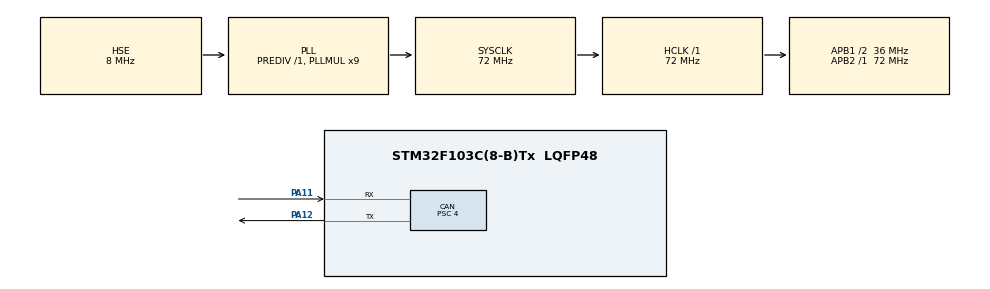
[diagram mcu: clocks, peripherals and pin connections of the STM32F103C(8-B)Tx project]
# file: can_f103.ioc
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CAN.BS1=CAN_BS1_11TQ
CAN.BS2=CAN_BS2_6TQ
CAN.CalculateBaudRate=500000
CAN.CalculateTimeBit=2000
CAN.CalculateTimeQuantum=111.11111111111111
CAN.Mode=CAN_MODE_LOOPBACK
CAN.Prescaler=4
CAN.SJW=CAN_SJW_1TQ
Mcu.Family=STM32F1
Mcu.Name=STM32F103C(8-B)Tx
Mcu.Package=LQFP48
NVIC.CAN1_RX1_IRQn=true\:0\:0\:false\:false\:true\:true\:true\:true
NVIC.CAN1_SCE_IRQn=true\:0\:0\:false\:false\:true\:true\:true\:true
NVIC.PriorityGroup=NVIC_PRIORITYGROUP_4
NVIC.TIM1_UP_IRQn=true\:0\:0\:false\:false\:true\:true\:true\:true
NVIC.USB_HP_CAN1_TX_IRQn=true\:0\:0\:false\:false\:true\:true\:true\:true
NVIC.USB_LP_CAN1_RX0_IRQn=true\:0\:0\:false\:false\:true\:true\:true\:true
PA11.Mode=CAN_Activate
PA11.Signal=CAN_RX
PA12.Mode=CAN_Activate
PA12.Signal=CAN_TX
PA13.Mode=Serial_Wire
PA13.Signal=SYS_JTMS-SWDIO
PA14.Mode=Serial_Wire
PA14.Signal=SYS_JTCK-SWCLK
PD0-OSC_IN.Mode=HSE-External-Oscillator
PD0-OSC_IN.Signal=RCC_OSC_IN
PD1-OSC_OUT.Mode=HSE-External-Oscillator
PD1-OSC_OUT.Signal=RCC_OSC_OUT
ProjectManager.HeapSize=0x200
ProjectManager.StackSize=0x400
ProjectManager.TargetToolchain=CMake
RCC.AHBFreq_Value=72000000
RCC.APB1CLKDivider=RCC_HCLK_DIV2
RCC.APB1Freq_Value=36000000
RCC.APB1TimFreq_Value=72000000
RCC.APB2Freq_Value=72000000
RCC.APB2TimFreq_Value=72000000
RCC.HCLKFreq_Value=72000000
RCC.PLLMUL=RCC_PLL_MUL9
RCC.PLLSourceVirtual=RCC_PLLSOURCE_HSE
RCC.SYSCLKFreq_VALUE=72000000
RCC.SYSCLKSource=RCC_SYSCLKSOURCE_PLLCLK
RCC.USBFreq_Value=72000000
TIM1.AutoReloadPreload=TIM_AUTORELOAD_PRELOAD_ENABLE
TIM1.Period=999
TIM1.Prescaler=71
VP_TIM1_VS_ClockSourceINT.Mode=Internal
board=custom

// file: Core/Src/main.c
/* USER CODE BEGIN Header */
/**
 ******************************************************************************
 * @file           : main.c
 * @brief          : Main program body
 ******************************************************************************
 * @attention
 *
 * Copyright (c) 2025 STMicroelectronics.
 * All rights reserved.
 *
 * This software is licensed under terms that can be found in the LICENSE file
 * in the root directory of this software component.
 * If no LICENSE file comes with this software, it is provided AS-IS.
 *
 ******************************************************************************
 */
/* USER CODE END Header */
#include "main.h"
#include "can.h"
#include "gpio.h"
#include "tim.h"

/* USER CODE BEGIN Includes */
#include "co.h"
#include "fifo.h"
#include "obj.h"
#include "params.h"
#include "pdo.h"
#include "port.h"
#include "sdo.h"

/* USER CODE END Includes */

void SystemClock_Config(void);

/* USER CODE BEGIN 0 */

device_data_t device_data = {.error_register = 0xFFFF,
                             .node_id = 1,
                             .heartbeat_time = 1000,
                             .device_name = "MY_CANOPEN_DEVICE",
                             .serial_number = 0x12345678,
                             .product_code = 0xABCD,
                             .baudrate = 250,
                             .operating_mode = 3,
                             .target_position = 0,
                             .actual_position = 0,
                             .target_velocity = 0,
                             .actual_velocity = 0,
                             .control_word = 0,
                             .status_word = 0,
                             .temperature = 25,
                             .error_history = {0}};

co_od_t object_dictionary[OBJECT_DICTIONARY_SIZE] = {
    /* --------------------------------------------------------------------------------------------------------------------------
     */
    /* | Parameter name   | Index | Sub index |   Data type     | Flag  | Data
       pointer | Min | Max        |*/
    /* --------------------------------------------------------------------------------------------------------------------------
     */
    {"Error register  ",
     &device_data.error_register,
     0x1000,
     0x00,
     OD_TYPE_UINT32,
     OD_RO,
     {0},
     {.u32 = 0xFFFFFFFF}},
    {"Error history[0]",
     &device_data.error_history[0],
     0x1001,
     0x00,
     OD_TYPE_INT8,
     OD_RO,
     {0},
     {.i8 = 127}},
    {"Device Name     ", &device_data.device_name, 0x1008, 0x00, OD_TYPE_STRING, OD_RO, {0}, {0}},
    {"Heartbeat_time  ",
     &device_data.heartbeat_time,
     0x1010,
     0x00,
     OD_TYPE_UINT32,
     OD_RO,
     {0},
     {.u32 = 0xFFFFFFFF}}};

co_obj_t canopen_server;

#define NODE 2

void HAL_CAN_RxFifo0MsgPendingCallback(CAN_HandleTypeDef *hcan) {
    co_handle_messages(&canopen_server, CAN_RX_FIFO0);
}

void HAL_CAN_RxFifo1MsgPendingCallback(CAN_HandleTypeDef *hcan) {
    co_handle_messages(&canopen_server, CAN_RX_FIFO1);
}

void canopen_sdo_callback(co_obj_t *canopen, co_msg_t *msg) {}

void rpdo_callback(co_msg_t *msg) {
    uint8_t lol;
    lol++;
}

void tpdo_callback(co_msg_t *msg) {
    uint8_t lol;
    lol++;
}

void rsdo_callback(co_msg_t *msg) {
    uint8_t lol;
    lol++;
}

void send_pdo(void){
    uint8_t data[] = {0x00, 0x00, 0x11, 0x11, 0x00, 0x00, 0x01, 0x23};
    co_transmite_pdo(&canopen_server, TPDO1(NODE), data, sizeof(data));
}

/* USER CODE END 0 */

int main(void) {

    /* MCU
     * Configuration--------------------------------------------------------*/

    /* Reset of all peripherals, Initializes the Flash interface and the
     * Systick. */
    HAL_Init();

    /* Configure the system clock */
    SystemClock_Config();

    /* Initialize all configured peripherals */
    MX_GPIO_Init();
    MX_CAN_Init();
    MX_TIM1_Init();
    /* USER CODE BEGIN 2 */

    /** CANopen Server example------------------------------------ */
    co_init(&canopen_server, CANOPEN_SERVER, NODE, COB_ID_STD);
    co_config_node_id(&canopen_server, NODE);

    co_subscribe_pdo(&canopen_server, RPDO1(NODE), rpdo_callback);
    co_subscribe_pdo(&canopen_server, TPDO1(NODE), tpdo_callback);
    co_subscribe_sdo(&canopen_server, RSDO1(NODE), rsdo_callback);
    HAL_TIM_Base_Start_IT(&htim1);
    /* USER CODE END 2 */

    /* Infinite loop */
    /* USER CODE BEGIN WHILE */
    while (1) {
        co_process_msg_rx(&canopen_server);
        co_process_msg_tx(&canopen_server);
        HAL_Delay(1);
        /* USER CODE END WHILE */

    }
}

void SystemClock_Config(void) {
    RCC_OscInitTypeDef RCC_OscInitStruct = {0};
    RCC_ClkInitTypeDef RCC_ClkInitStruct = {0};

    /** Initializes the RCC Oscillators according to the specified parameters
     * in the RCC_OscInitTypeDef structure.
     */
    RCC_OscInitStruct.OscillatorType = RCC_OSCILLATORTYPE_HSE;
    RCC_OscInitStruct.HSEState = RCC_HSE_ON;
    RCC_OscInitStruct.HSEPredivValue = RCC_HSE_PREDIV_DIV1;
    RCC_OscInitStruct.HSIState = RCC_HSI_ON;
    RCC_OscInitStruct.PLL.PLLState = RCC_PLL_ON;
    RCC_OscInitStruct.PLL.PLLSource = RCC_PLLSOURCE_HSE;
    RCC_OscInitStruct.PLL.PLLMUL = RCC_PLL_MUL9;
    if (HAL_RCC_OscConfig(&RCC_OscInitStruct) != HAL_OK) {
        Error_Handler();
    }

    /** Initializes the CPU, AHB and APB buses clocks
     */
    RCC_ClkInitStruct.ClockType =
        RCC_CLOCKTYPE_HCLK | RCC_CLOCKTYPE_SYSCLK | RCC_CLOCKTYPE_PCLK1 | RCC_CLOCKTYPE_PCLK2;
    RCC_ClkInitStruct.SYSCLKSource = RCC_SYSCLKSOURCE_PLLCLK;
    RCC_ClkInitStruct.AHBCLKDivider = RCC_SYSCLK_DIV1;
    RCC_ClkInitStruct.APB1CLKDivider = RCC_HCLK_DIV2;
    RCC_ClkInitStruct.APB2CLKDivider = RCC_HCLK_DIV1;

    if (HAL_RCC_ClockConfig(&RCC_ClkInitStruct, FLASH_LATENCY_2) != HAL_OK) {
        Error_Handler();
    }
}

void Error_Handler(void) {
    /* USER CODE BEGIN Error_Handler_Debug */
    /* User can add his own implementation to report the HAL error return state
     */
    __disable_irq();
    while (1) {
    }
    /* USER CODE END Error_Handler_Debug */
}
#ifdef USE_FULL_ASSERT
/**
 * @brief  Reports the name of the source file and the source line number
 *         where the assert_param error has occurred.
 * @param  file: pointer to the source file name
 * @param  line: assert_param error line source number
 * @retval None
 */
void assert_failed(uint8_t *file, uint32_t line) {
    /* USER CODE BEGIN 6 */
    /* User can add his own implementation to report the file name and line
       number, ex: printf("Wrong parameters value: file %s on line %d\r\n",
       file, line) */
    /* USER CODE END 6 */
}
#endif /* USE_FULL_ASSERT */
